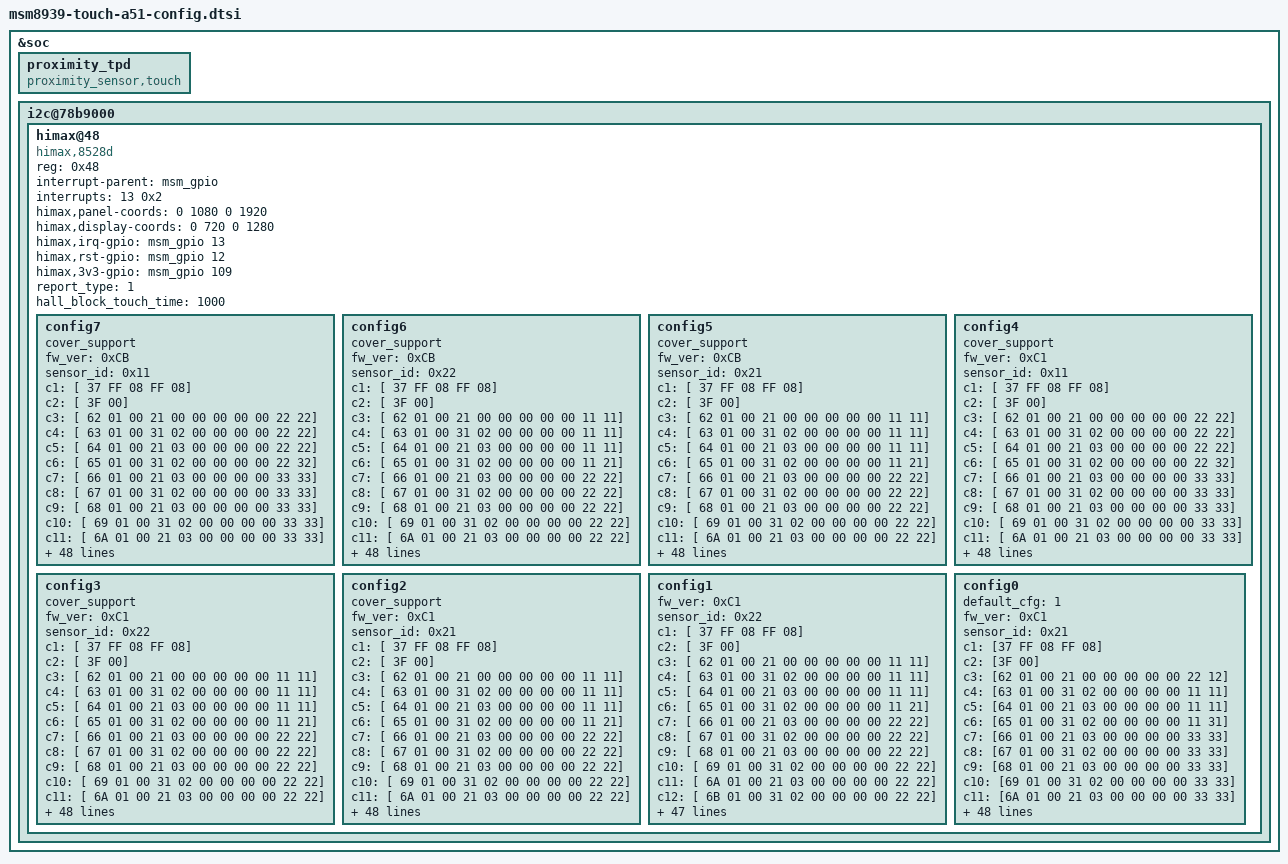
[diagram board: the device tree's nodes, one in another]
&soc {
	proximity_tpd {
		compatible = "proximity_sensor,touch";
	};

	i2c@78b9000 { /* BLSP1 QUP5 */
		himax@48 {
			compatible		= "himax,8528d";
			reg			= <0x48>;
			interrupt-parent	= <&msm_gpio>;
			interrupts		= <13 0x2>;
			himax,panel-coords	= <0 1080 0 1920>;
			himax,display-coords	= <0 720 0 1280>;
			himax,irq-gpio		= <&msm_gpio 13 0x00>;
			himax,rst-gpio		= <&msm_gpio 12 0x00>;
			himax,3v3-gpio		= <&msm_gpio 109 0x00>;
			report_type		= <1>;
			hall_block_touch_time	= <1000>;	/* msec */

			config7 {	//TPK
				cover_support;
				fw_ver     	= <0xCB>;
				sensor_id     	= <0x11>;
				c1  = [ 37 FF 08 FF 08];
				c2  = [ 3F 00];
				c3  = [ 62 01 00 21 00 00 00 00 00 22 22];
				c4  = [ 63 01 00 31 02 00 00 00 00 22 22];
				c5  = [ 64 01 00 21 03 00 00 00 00 22 22];
				c6  = [ 65 01 00 31 02 00 00 00 00 22 32];
				c7  = [ 66 01 00 21 03 00 00 00 00 33 33];
				c8  = [ 67 01 00 31 02 00 00 00 00 33 33];
				c9  = [ 68 01 00 21 03 00 00 00 00 33 33];
				c10 = [ 69 01 00 31 02 00 00 00 00 33 33];
				c11 = [ 6A 01 00 21 03 00 00 00 00 33 33];
				c12 = [ 6B 01 00 31 02 00 00 00 00 33 33];
				c13 = [ 6C 01 00 21 03 00 00 00 00 00 00];
				c14 = [ 6D 01 00 01 02 00 00 00 00 00 00];
				c15 = [ 6E 01 00 21 00 00 00 00 00 00 00];
				c16 = [ 6F 01 00 01 02 00 00 00 00 00 00];
				c17 = [ 70 01 00 31 00 00 00 00 00 00 00];
				c18 = [ 7B 03];
				c19 = [ 7C 00 D8 0C];
				c20 = [ 7F 00 04 0A 0A 04 00 00 00];
				c21 = [ A4 94 62 94 86];
				c22 = [ B4 06 01 02 02 02 02 0F 03 07 03
					07 03 07 08];
				c23 = [ B9 01 36];
				c24 = [ BA 00];
				c25 = [ BB 00];
				c26 = [ BC 00 00 00 00];
				c27 = [ BD 04 0C];
				c28 = [ C2 10 00 00 00 00 00 00 00];
				c29 = [ C5 0B 1D 00 10 19 1F 0B 1D 08 16];
				c30 = [ C6 18 10 18];
				c31 = [ C9 00 00 00 2D 28 26 24 22 20 1C
					1A 18 16 14 12 10 29 27 25 23
					21 1D 1B 19 17 15 13 11 00 00
					00 00 00 00 00 00 00 00 00 00
					00 00 00 00 00 00 00 00 00 00
					00 00 00 00 00 00 00 00 00 00
					00 00 00 00];
				c32 = [ CB 01 F5 FF FF 01 00 05 00 4F 00
					00 00];
				c33 = [ D0 06 01];
				c34 = [ D3 06 01];
				c35 = [ D5 29 00 00 00 00 00 00 00 00 00
					00 00 00 00 00 00];
				c36 = [ 40 42 5A
					5F 00 F2 10 00 00
					1C 0C 0B 0F 08 08 08 0F 10 0B
					2E 2B 40 40 50 00 00 00 00 00
					00 00];
				c37 = [ 40 94 0A F0 83 84 00
					44 22 0F 0F 83 4C 00 00
					11 00 41 42
					1F 58 00 12 00 00
					10 01 3C 64 00 00];
				c38 = [ 40 28 2F 2F 08 1F 00 00 00
					04 06 24 06 06 00 00 00];
				c39 = [ 40 30 2E 05 02 00 D8 0C 00 00 02
					03 90 00 00 00 00
					10 02 80 00 00 00 00 0C];
				c40 = [ 40 00 00 00 00 00 00 00 00
					BE 82 2D 00
					0F 19 A0 13
					00 00 04 38 07 80];
				c41 = [ 40 02 60 06 3B 53 33 08 00 7A 02
					23 53 67 0A
					03 5F 08 D8 57 64 00 00 B9 03
					40 56 75 00];
				c42 = [ 40 00 00 00 00 00 00 00 00];
				c43_1=[ 40 03 27 FF FF 04 26 19 FF 05 25
					18 FF 06 24 17 FF 07 23 16 FF
					02 22 15 FF 01 21 14 FF 00 20
					13];
				c43_2=[ 40 FF 08 1F 12 FF 09 1E 11 FF
					0A 1D 10 FF 0B 1C FF FF 0C 1B
					FF FF 0D 1A FF FF 0E FF 0F FF];
				c44_1=[ 40 33 00 C0 00 19 0A 28 00 00 00
					00 00 00 00 00 00 00 00 00 00
					11 C4 45 C5 48 5C 03 00 00 00
					5C];
				c44_2=[ 40 03 11 03 05 18];
				c45 = [ 40 00 00];
			};

			config6 {	//YFO
				cover_support;
				fw_ver     	= <0xCB>;
				sensor_id     	= <0x22>;
				c1  = [ 37 FF 08 FF 08];
				c2  = [ 3F 00];
				c3  = [ 62 01 00 21 00 00 00 00 00 11 11];
				c4  = [ 63 01 00 31 02 00 00 00 00 11 11];
				c5  = [ 64 01 00 21 03 00 00 00 00 11 11];
				c6  = [ 65 01 00 31 02 00 00 00 00 11 21];
				c7  = [ 66 01 00 21 03 00 00 00 00 22 22];
				c8  = [ 67 01 00 31 02 00 00 00 00 22 22];
				c9  = [ 68 01 00 21 03 00 00 00 00 22 22];
				c10 = [ 69 01 00 31 02 00 00 00 00 22 22];
				c11 = [ 6A 01 00 21 03 00 00 00 00 22 22];
				c12 = [ 6B 01 00 31 02 00 00 00 00 22 22];
				c13 = [ 6C 01 00 21 03 00 00 00 00 00 00];
				c14 = [ 6D 01 00 01 02 00 00 00 00 00 00];
				c15 = [ 6E 01 00 21 00 00 00 00 00 00 00];
				c16 = [ 6F 01 00 01 02 00 00 00 00 00 00];
				c17 = [ 70 01 00 31 00 00 00 00 00 00 00];
				c18 = [ 7B 03];
				c19 = [ 7C 00 D8 0C];
				c20 = [ 7F 00 04 0A 0A 04 00 00 00];
				c21 = [ A4 94 62 94 86];
				c22 = [ B4 06 01 02 02 02 02 0F 03 07 03
					07 03 07 08];
				c23 = [ B9 01 36];
				c24 = [ BA 00];
				c25 = [ BB 00];
				c26 = [ BC 00 00 00 00];
				c27 = [ BD 04 0C];
				c28 = [ C2 10 00 00 00 00 00 00 00];
				c29 = [ C5 0B 1E 00 10 1A 1F 0B 1E 08 16];
				c30 = [ C6 16 10 18];
				c31 = [ C9 00 00 00 2D 28 26 24 22 20 1C
					1A 18 16 14 12 10 29 27 25 23
					21 1D 1B 19 17 15 13 11 00 00
					00 00 00 00 00 00 00 00 00 00
					00 00 00 00 00 00 00 00 00 00
					00 00 00 00 00 00 00 00 00 00
					00 00 00 00];
				c32 = [ CB 01 F5 FF FF 01 00 05 00 4F 00
					00 00];
				c33 = [ D0 06 01];
				c34 = [ D3 06 01];
				c35 = [ D5 29 00 00 00 00 00 00 00 00 00
					00 00 00 00 00 00];
				c36 = [ 40 06 5A
					5F 00 F2 10 00 00
					1C 0C 0B 0F 09 09 09 0F 10 0B
					2E 2B 40 40 50 00 00 00 00 00
					00 00];
				c37 = [ 40 94 0A F0 83 84 00
					44 22 0F 0F 83 4C 00 00
					11 00 41 42
					1F 58 00 12 00 00
					10 01 3C 64 00 00];
				c38 = [ 40 28 2F 2F 05 1F 00 00 00
					04 06 24 06 06 00 00 00];
				c39 = [ 40 30 2E 05 02 00 D8 0C 00 00 02
					03 90 00 00 00 00
					10 02 80 00 00 00 00 0C];
				c40 = [ 40 00 00 00 00 00 00 00 00
					BE 82 2D 00
					0F 19 A0 13
					00 00 04 38 07 80];
				c41 = [ 40 02 60 06 3B 53 33 08 00 7A 02
					23 53 67 0A
					03 5F 08 D8 57 64 00 00 B9 03
					40 56 75 00];
				c42 = [ 40 00 00 00 00 00 00 00 00];
				c43_1=[ 40 03 27 FF FF 04 26 19 FF 05 25
					18 FF 06 24 17 FF 07 23 16 FF
					02 22 15 FF 01 21 14 FF 00 20
					13];
				c43_2=[ 40 FF 08 1F 12 FF 09 1E 11 FF
					0A 1D 10 FF 0B 1C FF FF 0C 1B
					FF FF 0D 1A FF FF 0E FF 0F FF];
				c44_1=[ 40 33 00 C0 00 19 0A 28 00 00 00
					00 00 00 00 00 00 00 00 00 00
					11 C4 36 A4 68 5C 03 00 00 00
					5C];
				c44_2=[ 40 03 11 03 05 18];
				c45 = [ 40 00 00];
			};

			config5 {	//PANA
				cover_support;
				fw_ver     	= <0xCB>;
				sensor_id     	= <0x21>;
				c1  = [ 37 FF 08 FF 08];
				c2  = [ 3F 00];
				c3  = [ 62 01 00 21 00 00 00 00 00 11 11];
				c4  = [ 63 01 00 31 02 00 00 00 00 11 11];
				c5  = [ 64 01 00 21 03 00 00 00 00 11 11];
				c6  = [ 65 01 00 31 02 00 00 00 00 11 21];
				c7  = [ 66 01 00 21 03 00 00 00 00 22 22];
				c8  = [ 67 01 00 31 02 00 00 00 00 22 22];
				c9  = [ 68 01 00 21 03 00 00 00 00 22 22];
				c10 = [ 69 01 00 31 02 00 00 00 00 22 22];
				c11 = [ 6A 01 00 21 03 00 00 00 00 22 22];
				c12 = [ 6B 01 00 31 02 00 00 00 00 22 22];
				c13 = [ 6C 01 00 21 03 00 00 00 00 00 00];
				c14 = [ 6D 01 00 01 02 00 00 00 00 00 00];
				c15 = [ 6E 01 00 21 00 00 00 00 00 00 00];
				c16 = [ 6F 01 00 01 02 00 00 00 00 00 00];
				c17 = [ 70 01 00 31 00 00 00 00 00 00 00];
				c18 = [ 7B 03];
				c19 = [ 7C 00 D8 0C];
				c20 = [ 7F 00 04 0A 0A 04 00 00 00];
				c21 = [ A4 94 62 94 86];
				c22 = [ B4 06 01 02 02 02 02 0F 03 07 03
					07 03 07 08];
				c23 = [ B9 01 36];
				c24 = [ BA 00];
				c25 = [ BB 00];
				c26 = [ BC 00 00 00 00];
				c27 = [ BD 04 0C];
				c28 = [ C2 10 00 00 00 00 00 00 00];
				c29 = [ C5 0B 1E 00 10 1A 1F 0B 1E 08 16];
				c30 = [ C6 16 10 18];
				c31 = [ C9 00 00 00 2D 28 26 24 22 20 1C
					1A 18 16 14 12 10 29 27 25 23
					21 1D 1B 19 17 15 13 11 00 00
					00 00 00 00 00 00 00 00 00 00
					00 00 00 00 00 00 00 00 00 00
					00 00 00 00 00 00 00 00 00 00
					00 00 00 00];
				c32 = [ CB 01 F5 FF FF 01 00 05 00 4F 00
					00 00];
				c33 = [ D0 06 01];
				c34 = [ D3 06 01];
				c35 = [ D5 29 00 00 00 00 00 00 00 00 00
					00 00 00 00 00 00];
				c36 = [ 40 22 5A
					5F 00 F2 10 00 00
					1C 0C 0B 0F 09 09 09 0F 10 0B
					2E 2B 40 40 50 00 00 00 00 00
					00 00];
				c37 = [ 40 94 0A F0 83 84 00
					44 22 0F 0F 83 4C 00 00
					11 00 41 42
					1F 58 00 12 00 00
					10 01 3C 64 00 00];
				c38 = [ 40 28 2F 2F 08 1F 00 00 00
					04 06 24 06 06 00 00 00];
				c39 = [ 40 30 2E 05 02 00 D8 0C 00 00 02
					03 90 00 00 00 00
					10 02 80 00 00 00 00 0C];
				c40 = [ 40 00 00 00 00 00 00 00 00
					BE 82 2D 00
					0F 19 A0 13
					00 00 04 38 07 80];
				c41 = [ 40 02 60 06 3B 53 33 08 00 7A 02
					23 53 67 0A
					03 5F 08 D8 57 64 00 00 B9 03
					40 56 75 00];
				c42 = [ 40 00 00 00 00 00 00 00 00];
				c43_1=[ 40 03 27 FF FF 04 26 19 FF 05 25
					18 FF 06 24 17 FF 07 23 16 FF
					02 22 15 FF 01 21 14 FF 00 20
					13];
				c43_2=[ 40 FF 08 1F 12 FF 09 1E 11 FF
					0A 1D 10 FF 0B 1C FF FF 0C 1B
					FF FF 0D 1A FF FF 0E FF 0F FF];
				c44_1=[ 40 33 00 C0 00 19 0A 28 00 00 00
					00 00 00 00 00 00 00 00 00 00
					11 C4 36 A4 68 5C 03 00 00 00
					5C];
				c44_2=[ 40 03 11 03 05 18];
				c45 = [ 40 00 00];
			};

			config4 {	//TPK
				cover_support;
				fw_ver     	= <0xC1>;
				sensor_id     	= <0x11>;
				c1  = [ 37 FF 08 FF 08];
				c2  = [ 3F 00];
				c3  = [ 62 01 00 21 00 00 00 00 00 22 22];
				c4  = [ 63 01 00 31 02 00 00 00 00 22 22];
				c5  = [ 64 01 00 21 03 00 00 00 00 22 22];
				c6  = [ 65 01 00 31 02 00 00 00 00 22 32];
				c7  = [ 66 01 00 21 03 00 00 00 00 33 33];
				c8  = [ 67 01 00 31 02 00 00 00 00 33 33];
				c9  = [ 68 01 00 21 03 00 00 00 00 33 33];
				c10 = [ 69 01 00 31 02 00 00 00 00 33 33];
				c11 = [ 6A 01 00 21 03 00 00 00 00 33 33];
				c12 = [ 6B 01 00 31 02 00 00 00 00 33 33];
				c13 = [ 6C 01 00 21 03 00 00 00 00 00 00];
				c14 = [ 6D 01 00 01 02 00 00 00 00 00 00];
				c15 = [ 6E 01 00 21 00 00 00 00 00 00 00];
				c16 = [ 6F 01 00 01 02 00 00 00 00 00 00];
				c17 = [ 70 01 00 31 00 00 00 00 00 00 00];
				c18 = [ 7B 03];
				c19 = [ 7C 00 D8 0C];
				c20 = [ 7F 00 04 0A 0A 04 00 00 00];
				c21 = [ A4 94 62 94 86];
				c22 = [ B4 06 01 02 02 02 02 0F 03 07 03
					07 03 07 08];
				c23 = [ B9 01 36];
				c24 = [ BA 00];
				c25 = [ BB 00];
				c26 = [ BC 00 00 00 00];
				c27 = [ BD 04 0C];
				c28 = [ C2 10 00 00 00 00 00 00 00];
				c29 = [ C5 0B 1C 00 10 1A 1F 0B 1E 08 16];
				c30 = [ C6 18 10 18];
				c31 = [ C9 00 00 00 2D 28 26 24 22 20 1C
					1A 18 16 14 12 10 29 27 25 23
					21 1D 1B 19 17 15 13 11 00 00
					00 00 00 00 00 00 00 00 00 00
					00 00 00 00 00 00 00 00 00 00
					00 00 00 00 00 00 00 00 00 00
					00 00 00 00];
				c32 = [ CB 01 F5 FF FF 01 00 05 00 4F 00
					00 00];
				c33 = [ D0 06 01];
				c34 = [ D3 06 01];
				c35 = [ D5 29 00 00 00 00 00 00 00 00 00
					00 00 00 00 00 00];
				c36 = [ 40 41 5A
					57 00 F2 10 00 00
					1C 0C 0B 0F 09 09 09 0F 10 0B
					2E 2B 40 40 50 00 00 00 00 00
					00 00];
				c37 = [ 40 94 0A F0 83 84 00
					44 22 0F 0F 83 4C 00 00
					11 00 41 42
					1F 58 00 12 00 00
					10 01 3C 64 00 00];
				c38 = [ 40 28 2F 2F 08 1F 00 00 00
					04 06 24 06 06 00 00 00];
				c39 = [ 40 30 2E 05 02 00 D8 0C 00 00 02
					03 90 00 00 00 00
					10 02 80 00 00 00 00 0C];
				c40 = [ 40 00 00 00 00 00 00 00 00
					BE 82 2D 00
					0F 19 A0 13
					00 00 04 38 07 80];
				c41 = [ 40 02 60 06 3B 53 33 08 00 7A 02
					23 53 67 0A
					03 5F 08 D8 57 64 00 00 B9 03
					40 56 75 00];
				c42 = [ 40 00 00 00 00 00 00 00 00];
				c43_1=[ 40 03 27 FF FF 04 26 19 FF 05 25
					18 FF 06 24 17 FF 07 23 16 FF
					02 22 15 FF 01 21 14 FF 00 20
					13];
				c43_2=[ 40 FF 08 1F 12 FF 09 1E 11 FF
					0A 1D 10 FF 0B 1C FF FF 0C 1B
					FF FF 0D 1A FF FF 0E FF 0F FF];
				c44_1=[ 40 33 00 C0 00 19 0A 28 00 00 00
					00 00 00 00 00 00 00 00 00 00
					11 C4 45 C5 48 5C 03 00 00 00
					5C];
				c44_2=[ 40 03 11 03 05 18];
				c45 = [ 40 00 00];
			};

			config3 {	//YFO
				cover_support;
				fw_ver     	= <0xC1>;
				sensor_id     	= <0x22>;
				c1  = [ 37 FF 08 FF 08];
				c2  = [ 3F 00];
				c3  = [ 62 01 00 21 00 00 00 00 00 11 11];
				c4  = [ 63 01 00 31 02 00 00 00 00 11 11];
				c5  = [ 64 01 00 21 03 00 00 00 00 11 11];
				c6  = [ 65 01 00 31 02 00 00 00 00 11 21];
				c7  = [ 66 01 00 21 03 00 00 00 00 22 22];
				c8  = [ 67 01 00 31 02 00 00 00 00 22 22];
				c9  = [ 68 01 00 21 03 00 00 00 00 22 22];
				c10 = [ 69 01 00 31 02 00 00 00 00 22 22];
				c11 = [ 6A 01 00 21 03 00 00 00 00 22 22];
				c12 = [ 6B 01 00 31 02 00 00 00 00 22 22];
				c13 = [ 6C 01 00 21 03 00 00 00 00 00 00];
				c14 = [ 6D 01 00 01 02 00 00 00 00 00 00];
				c15 = [ 6E 01 00 21 00 00 00 00 00 00 00];
				c16 = [ 6F 01 00 01 02 00 00 00 00 00 00];
				c17 = [ 70 01 00 31 00 00 00 00 00 00 00];
				c18 = [ 7B 03];
				c19 = [ 7C 00 D8 0C];
				c20 = [ 7F 00 04 0A 0A 04 00 00 00];
				c21 = [ A4 94 62 94 86];
				c22 = [ B4 06 01 02 02 02 03 07 03 07 03
					07 03 07 08];
				c23 = [ B9 01 36];
				c24 = [ BA 00];
				c25 = [ BB 00];
				c26 = [ BC 00 00 00 00];
				c27 = [ BD 04 0C];
				c28 = [ C2 10 00 00 00 00 00 00 00];
				c29 = [ C5 0B 1E 00 10 1A 1F 0B 1E 08 16];
				c30 = [ C6 16 10 18];
				c31 = [ C9 00 00 00 2D 28 26 24 22 20 1C
					1A 18 16 14 12 10 29 27 25 23
					21 1D 1B 19 17 15 13 11 00 00
					00 00 00 00 00 00 00 00 00 00
					00 00 00 00 00 00 00 00 00 00
					00 00 00 00 00 00 00 00 00 00
					00 00 00 00];
				c32 = [ CB 01 F5 FF FF 01 00 05 00 4F 00
					00 00];
				c33 = [ D0 06 01];
				c34 = [ D3 06 01];
				c35 = [ D5 29 00 00 00 00 00 00 00 00 00
					00 00 00 00 00 00];
				c36 = [ 40 05 5A
					5F 00 F0 10 00 00
					1C 0C 0B 0F 09 09 09 0F 10 0B
					2E 2B 40 40 50 00 00 00 00 00
					00 00];
				c37 = [ 40 94 0A F0 83 84 00
					44 22 0F 0F 83 4C 00 00
					11 00 41 42
					1F 58 00 12 00 00
					10 01 3C 64 00 00];
				c38 = [ 40 28 37 37 03 19 00 00 00
					04 06 24 06 06 00 00 00];
				c39 = [ 40 30 21 05 02 00 D8 0C 00 00 02
					03 90 00 00 00 00
					10 02 80 00 00 00 00 0C];
				c40 = [ 40 00 00 00 00 00 00 00 00
					BE 82 2D 00
					0F 19 A0 13
					00 00 04 38 07 80];
				c41 = [ 40 02 60 06 3B 53 33 08 00 7A 02
					23 53 67 0A
					03 5F 08 D8 57 64 00 00 B9 03
					40 56 75 00];
				c42 = [ 40 00 00 00 00 00 00 00 00];
				c43_1=[ 40 03 27 FF FF 04 26 19 FF 05 25
					18 FF 06 24 17 FF 07 23 16 FF
					02 22 15 FF 01 21 14 FF 00 20
					13];
				c43_2=[ 40 FF 08 1F 12 FF 09 1E 11 FF
					0A 1D 10 FF 0B 1C FF FF 0C 1B
					FF FF 0D 1A FF FF 0E FF 0F FF];
				c44_1=[ 40 33 00 C0 00 19 0A 28 00 00 00
					00 00 00 00 00 00 00 00 00 00
					11 A4 34 54 66 5C 00 00 00 00
					5C];
				c44_2=[ 40 03 11 03 05 18];
				c45 = [ 40 00 00];
			};

			config2 {	//PANA
				cover_support;
				fw_ver     	= <0xC1>;
				sensor_id     	= <0x21>;
				c1  = [ 37 FF 08 FF 08];
				c2  = [ 3F 00];
				c3  = [ 62 01 00 21 00 00 00 00 00 11 11];
				c4  = [ 63 01 00 31 02 00 00 00 00 11 11];
				c5  = [ 64 01 00 21 03 00 00 00 00 11 11];
				c6  = [ 65 01 00 31 02 00 00 00 00 11 21];
				c7  = [ 66 01 00 21 03 00 00 00 00 22 22];
				c8  = [ 67 01 00 31 02 00 00 00 00 22 22];
				c9  = [ 68 01 00 21 03 00 00 00 00 22 22];
				c10 = [ 69 01 00 31 02 00 00 00 00 22 22];
				c11 = [ 6A 01 00 21 03 00 00 00 00 22 22];
				c12 = [ 6B 01 00 31 02 00 00 00 00 22 22];
				c13 = [ 6C 01 00 21 03 00 00 00 00 00 00];
				c14 = [ 6D 01 00 01 02 00 00 00 00 00 00];
				c15 = [ 6E 01 00 21 00 00 00 00 00 00 00];
				c16 = [ 6F 01 00 01 02 00 00 00 00 00 00];
				c17 = [ 70 01 00 31 00 00 00 00 00 00 00];
				c18 = [ 7B 03];
				c19 = [ 7C 00 D8 0C];
				c20 = [ 7F 00 04 0A 0A 04 00 00 00];
				c21 = [ A4 94 62 94 86];
				c22 = [ B4 06 01 02 02 02 03 07 03 07 03
					07 03 07 08];
				c23 = [ B9 01 36];
				c24 = [ BA 00];
				c25 = [ BB 00];
				c26 = [ BC 00 00 00 00];
				c27 = [ BD 04 0C];
				c28 = [ C2 10 00 00 00 00 00 00 00];
				c29 = [ C5 0B 1E 00 10 1A 1F 0B 1E 08 16];
				c30 = [ C6 16 10 18];
				c31 = [ C9 00 00 00 2D 28 26 24 22 20 1C
					1A 18 16 14 12 10 29 27 25 23
					21 1D 1B 19 17 15 13 11 00 00
					00 00 00 00 00 00 00 00 00 00
					00 00 00 00 00 00 00 00 00 00
					00 00 00 00 00 00 00 00 00 00
					00 00 00 00];
				c32 = [ CB 01 F5 FF FF 01 00 05 00 4F 00
					00 00];
				c33 = [ D0 06 01];
				c34 = [ D3 06 01];
				c35 = [ D5 29 00 00 00 00 00 00 00 00 00
					00 00 00 00 00 00];
				c36 = [ 40 21 5A
					5F 00 F0 10 00 00
					1C 0C 0B 0F 09 09 09 0F 10 0B
					2E 2B 40 40 50 00 00 00 00 00
					00 00];
				c37 = [ 40 94 0A F0 83 84 00
					44 22 0F 0F 83 4C 00 00
					11 00 41 42
					1F 58 00 12 00 00
					10 01 3C 64 00 00];
				c38 = [ 40 28 37 37 08 19 00 00 00
					04 06 24 06 06 00 00 00];
				c39 = [ 40 30 21 05 02 00 D8 0C 00 00 02
					03 90 00 00 00 00
					10 02 80 00 00 00 00 0C];
				c40 = [ 40 00 00 00 00 00 00 00 00
					BE 82 2D 00
					0F 19 A0 13
					00 00 04 38 07 80];
				c41 = [ 40 02 60 06 3B 53 33 08 00 7A 02
					23 53 67 0A
					03 5F 08 D8 57 64 00 00 B9 03
					40 56 75 00];
				c42 = [ 40 00 00 00 00 00 00 00 00];
				c43_1=[ 40 03 27 FF FF 04 26 19 FF 05 25
					18 FF 06 24 17 FF 07 23 16 FF
					02 22 15 FF 01 21 14 FF 00 20
					13];
				c43_2=[ 40 FF 08 1F 12 FF 09 1E 11 FF
					0A 1D 10 FF 0B 1C FF FF 0C 1B
					FF FF 0D 1A FF FF 0E FF 0F FF];
				c44_1=[ 40 33 00 C0 00 19 0A 28 00 00 00
					00 00 00 00 00 00 00 00 00 00
					11 A4 34 54 66 5C 00 00 00 00
					5C];
				c44_2=[ 40 03 11 03 05 18];
				c45 = [ 40 00 00];
			};

			config1 {	//YFO
				fw_ver     	= <0xC1>;
				sensor_id     	= <0x22>;
				c1 =  [ 37 FF 08 FF 08];
				c2 =  [ 3F 00];
				c3 =  [ 62 01 00 21 00 00 00 00 00 11 11];
				c4 =  [ 63 01 00 31 02 00 00 00 00 11 11];
				c5 =  [ 64 01 00 21 03 00 00 00 00 11 11];
				c6 =  [ 65 01 00 31 02 00 00 00 00 11 21];
				c7 =  [ 66 01 00 21 03 00 00 00 00 22 22];
				c8 =  [ 67 01 00 31 02 00 00 00 00 22 22];
				c9 =  [ 68 01 00 21 03 00 00 00 00 22 22];
				c10 = [ 69 01 00 31 02 00 00 00 00 22 22];
				c11 = [ 6A 01 00 21 03 00 00 00 00 22 22];
				c12 = [ 6B 01 00 31 02 00 00 00 00 22 22];
				c13 = [ 6C 01 00 21 03 00 00 00 00 00 00];
				c14 = [ 6D 01 00 01 02 00 00 00 00 00 00];
				c15 = [ 6E 01 00 21 00 00 00 00 00 00 00];
				c16 = [ 6F 01 00 01 02 00 00 00 00 00 00];
				c17 = [ 70 01 00 31 00 00 00 00 00 00 00];
				c18 = [ 7B 03];
				c19 = [ 7C 00 D8 0C];
				c20 = [ 7F 00 04 0A 0A 04 00 00 00];
				c21 = [ A4 94 62 94 86];
				c22 = [ B4 06 01 02 02 02 03 07 04 07 04
					07 04 07 08];
				c23 = [ B9 01 36];
				c24 = [ BA 00];
				c25 = [ BB 00];
				c26 = [ BC 00 00 00 00];
				c27 = [ BD 04 0C];
				c28 = [ C2 10 00 00 00 00 00 00 00];
				c29 = [ C5 0B 1E 00 10 1A 1F 0B 1E 08 16];
				c30 = [ C6 15 10 1E];
				c31 = [ C9 00 00 00 2D 28 26 24 22 20 1C
					1A 18 16 14 12 10 29 27 25 23
					21 1D 1B 19 17 15 13 11 00 00
					00 00 00 00 00 00 00 00 00 00
					00 00 00 00 00 00 00 00 00 00
					00 00 00 00 00 00 00 00 00 00
					00 00 00 00];
				c32 = [ CB 01 F5 FF FF 01 00 05 00 5F 00
					00 00];
				c33 = [ D0 06 01];
				c34 = [ D3 06 01];
				c35 = [ D5 29 00 00 00 00 00 00 00 00 00
					00 00 00 00 00 00];
				c36 = [ 40 04 5A
					5F 00 F0 10 00 00
					1C 0C 0B 0F 09 09 09 0F 10 0B
					24 20 30 30 3C 00 00 00 00 00
					00 00];
				c37 = [ 40 94 0A F0 83 84 00
					48 24 0F 0F 83 3C 00 00
					11 00 41 42
					0F 2F 00 12 00 00
					10 01 3C 64 00 00];
				c38 = [ 40 18 37 37 05 19 00 00 00
					04 06 24 06 06 00 00 00];
				c39 = [ 40 30 1B 05 02 00 D8 0C 00 00 02
					03 90 00 00 00 00
					10 02 80 00 00 00 00 0C];
				c40 = [ 40 00 00 00 00 00 00 00 00
					A0 82 2D 00
					0F 19 A0 13
					00 00 04 38 07 80];
				c41 = [ 40 02 60 06 3B 53 33 08 00 7A 02
					23 53 67 0A
					03 5F 08 D8 57 64 00 00 B9 03
					40 56 75 00];
				c42 = [ 40 00 00 00 00 00 00 00 00];
				c43_1=[ 40 03 27 FF FF 04 26 19 FF 05 25
					18 FF 06 24 17 FF 07 23 16 FF
					02 22 15 FF 01 21 14 FF 00 20
					13];
				c43_2=[ 40 FF 08 1F 12 FF 09 1E 11 FF
					0A 1D 10 FF 0B 1C FF FF 0C 1B
					FF FF 0D 1A FF FF 0E FF 0F FF];
				c44_1=[ 40 33 00 C0 00 19 0A 28 00 00 00
					00 00 00 00 00 00 00 00 00 00
					27 96 35 75 56 5C 03 00 00 00
					5C];
				c44_2=[ 40 03 11 03 05 18];
				c45 = [ 40 00 00];
			};

			config0 {	//O-film semi
				default_cfg   	= <1>;
				fw_ver     	= <0xC1>;
				sensor_id     	= <0x21>;
				c1 =[37 FF 08 FF 08];
				c2 =[3F 00];
				c3 =[62 01 00 21 00 00 00 00 00 22 12];
				c4 =[63 01 00 31 02 00 00 00 00 11 11];
				c5 =[64 01 00 21 03 00 00 00 00 11 11];
				c6 =[65 01 00 31 02 00 00 00 00 11 31];
				c7 =[66 01 00 21 03 00 00 00 00 33 33];
				c8 =[67 01 00 31 02 00 00 00 00 33 33];
				c9 =[68 01 00 21 03 00 00 00 00 33 33];
				c10 =[69 01 00 31 02 00 00 00 00 33 33];
				c11 =[6A 01 00 21 03 00 00 00 00 33 33];
				c12 =[6B 01 00 31 02 00 00 00 00 33 23];
				c13 =[6C 01 00 21 03 00 00 00 00 00 00];
				c14 =[6D 01 00 01 02 00 00 00 00 00 00];
				c15 =[6E 01 00 21 00 00 00 00 00 00 00];
				c16 =[6F 01 00 01 02 00 00 00 00 00 00];
				c17 =[70 01 00 31 00 00 00 00 00 00 00];
				c18 =[7B 03];
				c19 =[7C 00 D8 0C];
				c20 =[7F 00 04 0A 0A 04 00 00 00];
				c21 =[A4 94 62 94 86];
				c22 =[B4 05 01 02 02 02 03 0F 04 07 04
				          07 04 07 08];
				c23 =[B9 01 56];
				c24 =[BA 00];
				c25 =[BB 00];
				c26 =[BC 00 00 00 00];
				c27 =[BD 04 0C];
				c28 =[C2 10 00 00 00 00 00 00 00];
				c29 =[C5 0B 1B 00 10 1A 1E 0B 1A 08 16];
				c30 =[C6 15 10 1A];
				c31 =[C9 00 00 00 2D 28 26 24 22 20 1C
				          1A 18 16 14 12 10 29 27 25 23
				          21 1D 1B 19 17 15 13 11 00 00
				          00 00 00 00 00 00 00 00 00 00
				          00 00 00 00 00 00 00 00 00 00
				          00 00 00 00 00 00 00 00 00 00
				          00 00 00 00];
				c32 =[CB 01 F5 FF FF 01 00 05 00 7F 00
				          00 00];
				c33 =[D0 06 01];
				c34 =[D3 06 01];
				c35 =[D5 29 00 00 00 00 00 00 00 00 00
				          00 00 00 00 00 00];
				c36 =[40 09 5A
				          5F 00 F0 10 00 00
				          1C 0C 0B 0F 09 09 09 08 08 08
				          24 20 40 40 3C 00 00 00 00 00
				          00 00];
				c37 =[40 94 0A F0 83 84 00
				          48 24 0F 0F 83 3C 00 00
				          11 00 41 42
				          0F 28 00 12 00 00
				          10 02 3C 64 00 00];
				c38 =[40 18 3F 3F 02 19 00 00 00
				          04 06 24 05 05 00 00 00];
				c39 =[40 30 1F 05 02 00 D8 0C 00 00 02
				          03 80 00 00 00 00
				          10 02 80 00 00 00 00 0C];
				c40 =[40 00 00 00 00 00 00 00 00
				          A0 82 2D 00
				          0F 19 A0 13
				          00 00 04 38 07 80];
				c41 =[40 02 60 06 3B 53 33 08 00 7A 02
				          23 53 67 0A
				          03 5F 08 D8 57 64 00 00 B9 03
				          40 56 75 00];
				c42 =[40 00 00 00 00 00 00 00 00];
				c43_1 =[40 03 27 FF FF 04 26 19 FF 05 25
				             18 FF 06 24 17 FF 07 23 16 FF
				             02 22 15 FF 01 21 14 FF 00 20
				             13];
				c43_2 =[40 FF 08 1F 12 FF 09 1E 11 FF
				             0A 1D 10 FF 0B 1C FF FF 0C 1B
				             FF FF 0D 1A FF FF 0E FF 0F FF];
				c44_1 =[40 A3 00 20 00 13 1E 32 00 00 00
				             00 00 00 00 00 00 00 00 00 00
				             00 00 00 00 00 00 00 00 00 00
				             56];
				c44_2 =[40 02 12 02 00 04];
				c45   =[40 00 00];
			};
		};
	};
};
